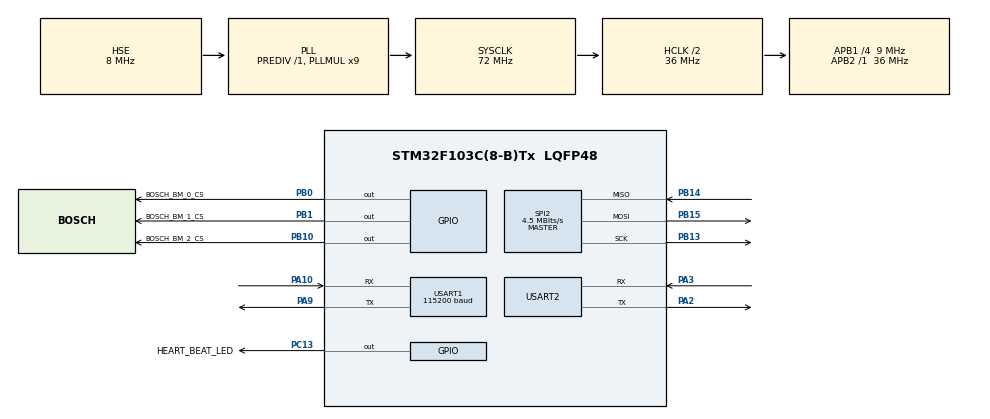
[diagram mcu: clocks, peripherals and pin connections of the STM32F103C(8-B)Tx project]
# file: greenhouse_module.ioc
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Mcu.Family=STM32F1
RCC.PLLSourceVirtual=RCC_PLLSOURCE_HSE
FREERTOS.Tasks01=heartBeat,0,128,heartBeatTask,Default,NULL,Static,heartBeatBuffer,heartBeatControlBlock;sensorMonitor,-3,256,sensorMonitorTask,Default,NULL,Static,sensorMonitorBuffer,sensorMonitorControlBlock;debugConsole,-3,128,debugConsoleTask,Default,NULL,Static,debugConsoleTasBuffer,debugConsoleTasControlBlock
PD1-OSC_OUT.Mode=HSE-External-Oscillator
PA10.Mode=Asynchronous
SPI2.VirtualType=VM_MASTER
USART1.BaudRate=115200
PC13-TAMPER-RTC.Signal=GPIO_Output
PB0.GPIO_Label=BOSCH_BM_0_CS
NVIC.TIM1_UP_IRQn=true\:0\:0\:false\:false\:true\:false\:false\:true
PD0-OSC_IN.Signal=RCC_OSC_IN
RCC.APB1CLKDivider=RCC_HCLK_DIV4
PB13.Signal=SPI2_SCK
PB15.Signal=SPI2_MOSI
NVIC.USART2_IRQn=true\:5\:0\:false\:false\:true\:true\:true\:true
RCC.SYSCLKSource=RCC_SYSCLKSOURCE_PLLCLK
ProjectManager.StackSize=0x400
PD1-OSC_OUT.Signal=RCC_OSC_OUT
PB0.GPIO_Speed=GPIO_SPEED_FREQ_LOW
PA13.Signal=SYS_JTMS-SWDIO
PA3.Mode=Asynchronous
PA9.Mode=Asynchronous
SPI2.CLKPolarity=SPI_POLARITY_LOW
ProjectManager.TargetToolchain=Makefile
PB10.GPIO_Label=BOSCH_BM_2_CS
RCC.HCLKFreq_Value=36000000
RCC.APB2TimFreq_Value=36000000
PA9.Signal=USART1_TX
RCC.USBFreq_Value=72000000
RCC.AHBFreq_Value=36000000
SPI2.BaudRatePrescaler=SPI_BAUDRATEPRESCALER_2
PD0-OSC_IN.Mode=HSE-External-Oscillator
PB10.Signal=GPIO_Output
PB14.Signal=SPI2_MISO
board=custom
PC13-TAMPER-RTC.GPIO_Label=HEART_BEAT_LED
RCC.PLLMUL=RCC_PLL_MUL9
PB15.Mode=Full_Duplex_Master
RCC.APB2Freq_Value=36000000
PA14.Mode=Serial_Wire
PB14.Mode=Full_Duplex_Master
VP_SYS_VS_tim1.Mode=TIM1
PB1.GPIO_Label=BOSCH_BM_1_CS
SPI2.CalculateBaudRate=4.5 MBits/s
RCC.AHBCLKDivider=RCC_SYSCLK_DIV2
VP_FREERTOS_VS_CMSIS_V1.Mode=CMSIS_V1
PA13.Mode=Serial_Wire
Mcu.Name=STM32F103C(8-B)Tx
PA2.Signal=USART2_TX
RCC.SYSCLKFreq_VALUE=72000000
Mcu.Package=LQFP48
PB1.Signal=GPIO_Output
NVIC.TimeBase=TIM1_UP_IRQn
SPI2.Mode=SPI_MODE_MASTER
USART2.VirtualMode=VM_ASYNC
USART1.VirtualMode=VM_ASYNC
NVIC.TimeBaseIP=TIM1
PA10.Signal=USART1_RX
PA14.Signal=SYS_JTCK-SWCLK
ProjectManager.HeapSize=0x200
NVIC.PriorityGroup=NVIC_PRIORITYGROUP_4
RCC.APB1TimFreq_Value=18000000
PA2.Mode=Asynchronous
SPI2.Direction=SPI_DIRECTION_2LINES
PB13.Mode=Full_Duplex_Master
NVIC.USART1_IRQn=true\:5\:0\:false\:false\:true\:false\:true\:true
RCC.APB1Freq_Value=9000000
PB0.Signal=GPIO_Output
PB0.GPIO_PuPd=GPIO_NOPULL
PA3.Signal=USART2_RX

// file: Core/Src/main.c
/* USER CODE BEGIN Header */
/* USER CODE END Header */
#include "main.h"
#include "cmsis_os.h"
#include "spi.h"
#include "usart.h"
#include "gpio.h"

void SystemClock_Config(void);
void MX_FREERTOS_Init(void);

int main(void)
{

  /* MCU Configuration--------------------------------------------------------*/

  /* Reset of all peripherals, Initializes the Flash interface and the Systick. */
  HAL_Init();

  /* Configure the system clock */
  SystemClock_Config();

  /* Initialize all configured peripherals */
  MX_GPIO_Init();
  MX_USART1_UART_Init();
  MX_SPI2_Init();
  MX_USART2_UART_Init();

  /* Call init function for freertos objects (in freertos.c) */
  MX_FREERTOS_Init();
  /* Start scheduler */
  osKernelStart();

  /* We should never get here as control is now taken by the scheduler */
  /* Infinite loop */

}

void SystemClock_Config(void)
{
  RCC_OscInitTypeDef RCC_OscInitStruct = {0};
  RCC_ClkInitTypeDef RCC_ClkInitStruct = {0};

  /** Initializes the RCC Oscillators according to the specified parameters
  * in the RCC_OscInitTypeDef structure.
  */
  RCC_OscInitStruct.OscillatorType = RCC_OSCILLATORTYPE_HSE;
  RCC_OscInitStruct.HSEState = RCC_HSE_ON;
  RCC_OscInitStruct.HSEPredivValue = RCC_HSE_PREDIV_DIV1;
  RCC_OscInitStruct.HSIState = RCC_HSI_ON;
  RCC_OscInitStruct.PLL.PLLState = RCC_PLL_ON;
  RCC_OscInitStruct.PLL.PLLSource = RCC_PLLSOURCE_HSE;
  RCC_OscInitStruct.PLL.PLLMUL = RCC_PLL_MUL9;
  if (HAL_RCC_OscConfig(&RCC_OscInitStruct) != HAL_OK)
  {
    Error_Handler();
  }
  /** Initializes the CPU, AHB and APB buses clocks
  */
  RCC_ClkInitStruct.ClockType = RCC_CLOCKTYPE_HCLK|RCC_CLOCKTYPE_SYSCLK
                              |RCC_CLOCKTYPE_PCLK1|RCC_CLOCKTYPE_PCLK2;
  RCC_ClkInitStruct.SYSCLKSource = RCC_SYSCLKSOURCE_PLLCLK;
  RCC_ClkInitStruct.AHBCLKDivider = RCC_SYSCLK_DIV2;
  RCC_ClkInitStruct.APB1CLKDivider = RCC_HCLK_DIV4;
  RCC_ClkInitStruct.APB2CLKDivider = RCC_HCLK_DIV1;

  if (HAL_RCC_ClockConfig(&RCC_ClkInitStruct, FLASH_LATENCY_2) != HAL_OK)
  {
    Error_Handler();
  }
}

 /**
  * @brief  Period elapsed callback in non blocking mode
  * @note   This function is called  when TIM1 interrupt took place, inside
  * HAL_TIM_IRQHandler(). It makes a direct call to HAL_IncTick() to increment
  * a global variable "uwTick" used as application time base.
  * @param  htim : TIM handle
  * @retval None
  */
void HAL_TIM_PeriodElapsedCallback(TIM_HandleTypeDef *htim)
{
  if (htim->Instance == TIM1) {
    HAL_IncTick();
  }
}

void Error_Handler(void)
{
}

/************************ (C) COPYRIGHT STMicroelectronics *****END OF FILE****/

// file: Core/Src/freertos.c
/* USER CODE BEGIN Header */
/**
  ******************************************************************************
  * File Name          : freertos.c
  * Description        : Code for freertos applications
  ******************************************************************************
  * @attention
  *
  * <h2><center>&copy; Copyright (c) 2021 STMicroelectronics.
  * All rights reserved.</center></h2>
  *
  * This software component is licensed by ST under Ultimate Liberty license
  * SLA0044, the "License"; You may not use this file except in compliance with
  * the License. You may obtain a copy of the License at:
  *                             www.st.com/SLA0044
  *
  ******************************************************************************
  */
/* USER CODE END Header */

#include "FreeRTOS.h"
#include "task.h"
#include "main.h"
#include "cmsis_os.h"

/* USER CODE BEGIN Includes */
#include "green_house_module.h"
/* USER CODE END Includes */

osThreadId heartBeatHandle;
uint32_t heartBeatBuffer[ 128 ];
osStaticThreadDef_t heartBeatControlBlock;
osThreadId sensorMonitorHandle;
uint32_t sensorMonitorBuffer[ 256 ];
osStaticThreadDef_t sensorMonitorControlBlock;
osThreadId debugConsoleHandle;
uint32_t debugConsoleTasBuffer[ 128 ];
osStaticThreadDef_t debugConsoleTasControlBlock;

void heartBeatTask(void const * argument);
void sensorMonitorTask(void const * argument);
void debugConsoleTask(void const * argument);

void MX_FREERTOS_Init(void); /* (MISRA C 2004 rule 8.1) */

/* GetIdleTaskMemory prototype (linked to static allocation support) */
void vApplicationGetIdleTaskMemory( StaticTask_t **ppxIdleTaskTCBBuffer, StackType_t **ppxIdleTaskStackBuffer, uint32_t *pulIdleTaskStackSize );

/* USER CODE BEGIN GET_IDLE_TASK_MEMORY */
static StaticTask_t xIdleTaskTCBBuffer;
static StackType_t xIdleStack[configMINIMAL_STACK_SIZE];

void vApplicationGetIdleTaskMemory( StaticTask_t **ppxIdleTaskTCBBuffer, StackType_t **ppxIdleTaskStackBuffer, uint32_t *pulIdleTaskStackSize )
{
  *ppxIdleTaskTCBBuffer = &xIdleTaskTCBBuffer;
  *ppxIdleTaskStackBuffer = &xIdleStack[0];
  *pulIdleTaskStackSize = configMINIMAL_STACK_SIZE;
  /* place for user code */
}
/* USER CODE END GET_IDLE_TASK_MEMORY */

void MX_FREERTOS_Init(void) {

  /* Create the thread(s) */
  /* definition and creation of heartBeat */
  osThreadStaticDef(heartBeat, heartBeatTask, osPriorityNormal, 0, 128, heartBeatBuffer, &heartBeatControlBlock);
  heartBeatHandle = osThreadCreate(osThread(heartBeat), NULL);

  /* definition and creation of sensorMonitor */
  osThreadStaticDef(sensorMonitor, sensorMonitorTask, osPriorityIdle, 0, 256, sensorMonitorBuffer, &sensorMonitorControlBlock);
  sensorMonitorHandle = osThreadCreate(osThread(sensorMonitor), NULL);

  /* definition and creation of debugConsole */
  osThreadStaticDef(debugConsole, debugConsoleTask, osPriorityIdle, 0, 128, debugConsoleTasBuffer, &debugConsoleTasControlBlock);
  debugConsoleHandle = osThreadCreate(osThread(debugConsole), NULL);

}

void heartBeatTask(void const * argument)
{
  /* USER CODE BEGIN heartBeatTask */
  /* Infinite loop */
  for(;;)
  {
    heartBeat();
  }
  /* USER CODE END heartBeatTask */
}

void sensorMonitorTask(void const * argument)
{
  /* USER CODE BEGIN sensorMonitorTask */
  /* Infinite loop */
  for(;;)
  {
    sensorMonitor();
    osDelay(1);
  }
  /* USER CODE END sensorMonitorTask */
}

void debugConsoleTask(void const * argument)
{
  /* USER CODE BEGIN debugConsoleTask */
  /* Infinite loop */
  for(;;)
  {
    startLogger();
    osDelay(1);
  }
  /* USER CODE END debugConsoleTask */
}

/************************ (C) COPYRIGHT STMicroelectronics *****END OF FILE****/
